# CEC1734_S0_2HW register map
Vendor: Microchip
Registers are 32-bit, read-write, reset 0x0 unless marked. A register's access mark holds for its fields unless they carry their own. Addresses are absolute, and some are shared; only a register's first bit layout is shown; [hi:lo] are bit positions; {n}, {i} and the like mark numbered series.

## TFDP
0x40008C00 MSDATA 8-bit
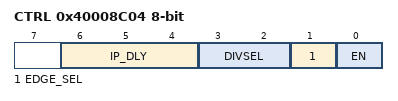
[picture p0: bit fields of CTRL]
0x40008C04 CTRL 8-bit
  [6:4] IP_DLY — Inter-packet Delay. The delay is in terms of TFDP Debug output clocks.
  [3:2] DIVSEL — Clock Divider Select.
  [1] EDGE_SEL — 1= Data is shifted out on the falling edge of the debug clock, 0= Data is shifted out on the rising edge of the debug clock (Default)
  [0] EN — Enable. 1=Clock enabled, 0=Clock is disabled (Default)

## HTM0
0x40009800 PRLD 16-bit
0x40009804 CTRL 16-bit
  [0] CTRL — 1= The Hibernation Timer has a resolution of 0.125s per LSB, which yields a maximum time in excess of 2 hours. 0= The Hibernation Timer has a resolution of 30.5us per LSB, which yields a maximum time of ~2seconds.
0x40009808 CNT 16-bit ro

## HTM1
0x40009820 PRLD 16-bit
0x40009824 CTRL 16-bit
  [0] CTRL — 1= The Hibernation Timer has a resolution of 0.125s per LSB, which yields a maximum time in excess of 2 hours. 0= The Hibernation Timer has a resolution of 30.5us per LSB, which yields a maximum time of ~2seconds.
0x40009828 CNT 16-bit ro

## VTR_REG_BANK
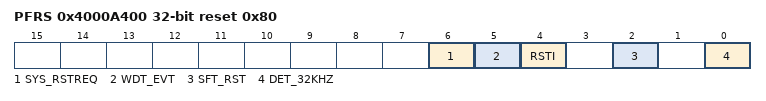
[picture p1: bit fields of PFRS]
0x4000A400 PFRS reset 0x80
  [6] SYS_RSTREQ — This bit is set to '1b' if a RESET_SYS was triggered by an ARM SYSRESETREQ event. This bit is cleared to '0b' when written with a '1b'; writes of a '0b' have no effect. (R/WC)
  [5] WDT_EVT — This bit is set to '1b' if a RESET_SYS was triggered by a Watchdog Timer event. This bit is cleared to '0b' when written with a '1b'; writes of a '0b' have no effect. (R/WC)
  [4] RSTI — This bit is set to '1b' if a RESET_SYS was triggered by a low signal on the RESETI# input pin. This bit is cleared to '0b' when written with a '1b'; writes of a '0b' have no effect. (R/WC)
  [2] SFT_RST — This bit is set to '1b' if a was triggered by an assertion of the SOFT_SYS_RESET bit in the System Reset Register. This bit is cleared to '0b' when written with a '1b'; writes of a '0b' have no effect. (R/WC)
  [0] DET_32KHZ — Detect 32KHz Clock Input (R/WC)

## OTP
{0x40082044+i} WR_LOCK{i} 8-bit (i=0..3)
  [7:0] WL{i} — When any of the bits are set, the corresponding 32byte range in the OTP is not writable.
{0x40082048+i} RD_LOCK{i} 8-bit (i=0..3)
  [7:0] RL{i} — When any of the bits are set, the corresponding 32byte range in the OTP is not readable.
0x4008204C WR_FINE_LCK
  [31:0] WR_FINE_LCK — Each bit locks write to a byte in the OTP range starting byte 320 to 351 0=Not Locked 1=Locked.
0x40082050 RD_FINE_LCK
  [31:0] RD_FINE_LCK — Each bit locks read to a byte in the OTP range starting byte 320 to 351 0=Not Locked 1=Locked.

## GCR
0x400FFF07 LDN 8-bit
0x400FFF1C DEV_REV 8-bit ro reset 0xA0
0x400FFF1D DEV_SUBID 8-bit ro reset 0x21
0x400FFF1E DEV_ID 16-bit ro reset 0x24
0x400FFF20 LEG_DEV_ID 8-bit ro reset 0xFE
0x400FFF21 LEG_DEV_REV 8-bit ro reset 0xA0
0x400FFF24 OTP_ID 8-bit ro
0x400FFF25 VLD_ID 8-bit ro
0x400FFF26 BR_REV_ID 8-bit ro

## SFR
0xE000E004 ICTR ro reset not defined — Interrupt Controller Type Register (power-on value xxxxxxxxxxxxxxxxxxxxxxxxxxxxxxxx)
  [3:0] INTLINESNUM — Number of interrupt lines supported by NVIC in granularities of 32.

## SysTick
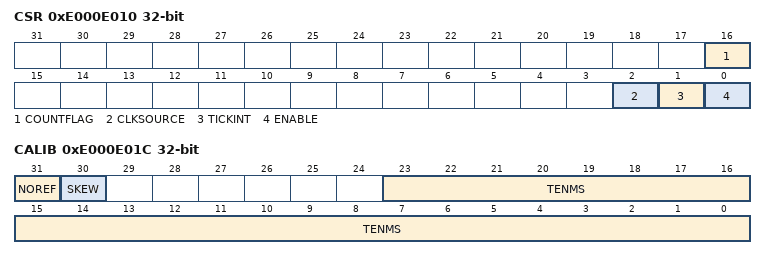
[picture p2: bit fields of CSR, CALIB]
0xE000E010 CSR
  [16] COUNTFLAG — Timer counted to 0 since last read of register
  [2] CLKSOURCE — Clock Source 0=external, 1=processor
    0=External clock; 1=Processor clock
  [1] TICKINT — SysTick Exception Request Enable
    0=Counting down to 0 does not assert the SysTick exception request; 1=Counting down to 0 asserts the SysTick exception request
  [0] ENABLE — SysTick Counter Enable
    0=Counter disabled; 1=Counter enabled
0xE000E014 RVR reset not defined
  [23:0] RELOAD — Value to load into the SysTick Current Value Register when the counter reaches 0
0xE000E018 CVR reset not defined
  [23:0] CURRENT — Current value at the time the register is accessed
0xE000E01C CALIB ro
  [31] NOREF — No Separate Reference Clock
    0=The reference clock is provided; 1=The reference clock is not provided
  [30] SKEW — TENMS is rounded from non-integer ratio
    0=10ms calibration value is exact; 1=10ms calibration value is inexact, because of the clock frequency
  [23:0] TENMS — Reload value to use for 10ms timing

## NVIC
0xE000E100 ISER0
  [31:0] SETENA — Interrupt set enable bits
0xE000E180 ICER0
  [31:0] CLRENA — Interrupt clear-enable bits
0xE000E200 ISPR0
  [31:0] SETPEND — Interrupt set-pending bits
0xE000E280 ICPR0
  [31:0] CLRPEND — Interrupt clear-pending bits
0xE000E300 IABR0
  [31:0] ACTIVE — Interrupt active bits
{0xE000E400+i} IP{i} 8-bit (i=0..7)
  [2:0] PRI0 — Priority of interrupt n
0xE000EF00 STIR wo reset not defined
  [8:0] INTID — Interrupt ID to trigger

## FPU
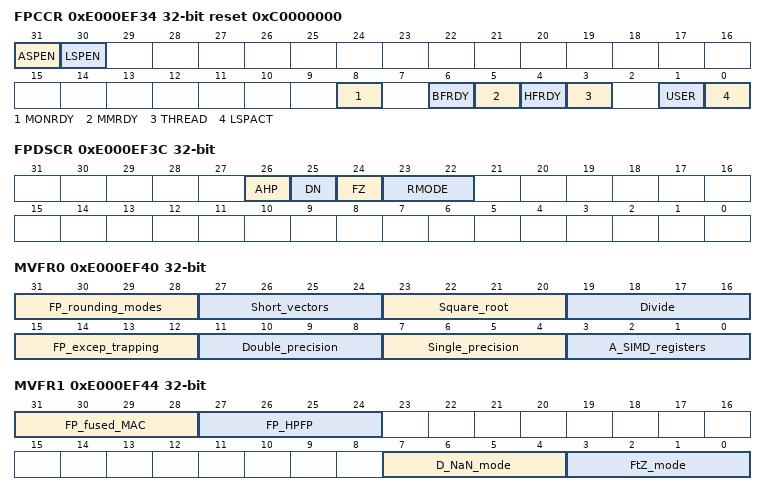
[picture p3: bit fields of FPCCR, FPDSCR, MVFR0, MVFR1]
0xE000EF34 FPCCR reset 0xC0000000
  [31] ASPEN, [30] LSPEN, [8] MONRDY, [6] BFRDY, [5] MMRDY, [4] HFRDY, [3] THREAD, [1] USER, [0] LSPACT
0xE000EF38 FPCAR reset not defined
  [31:3] ADDRESS — Address for FP registers in exception stack frame
0xE000EF3C FPDSCR
  [26] AHP — Default value for FPSCR.AHP
  [25] DN — Default value for FPSCR.DN
  [24] FZ — Default value for FPSCR.FZ
  [23:22] RMODE — Default value for FPSCR.RMODE
    0=RN (Round to Nearest); 1=RP (Round towards Positive Infinity); 2=RM (Round towards Negative Infinity); 3=RZ (Round towards Zero)
0xE000EF40 MVFR0 ro reset not defined
  [31:28] FP_rounding_modes, [27:24] Short_vectors, [23:20] Square_root, [19:16] Divide, [15:12] FP_excep_trapping, [11:8] Double_precision, [7:4] Single_precision, [3:0] A_SIMD_registers
0xE000EF44 MVFR1 ro reset not defined
  [31:28] FP_fused_MAC, [27:24] FP_HPFP, [7:4] D_NaN_mode, [3:0] FtZ_mode
